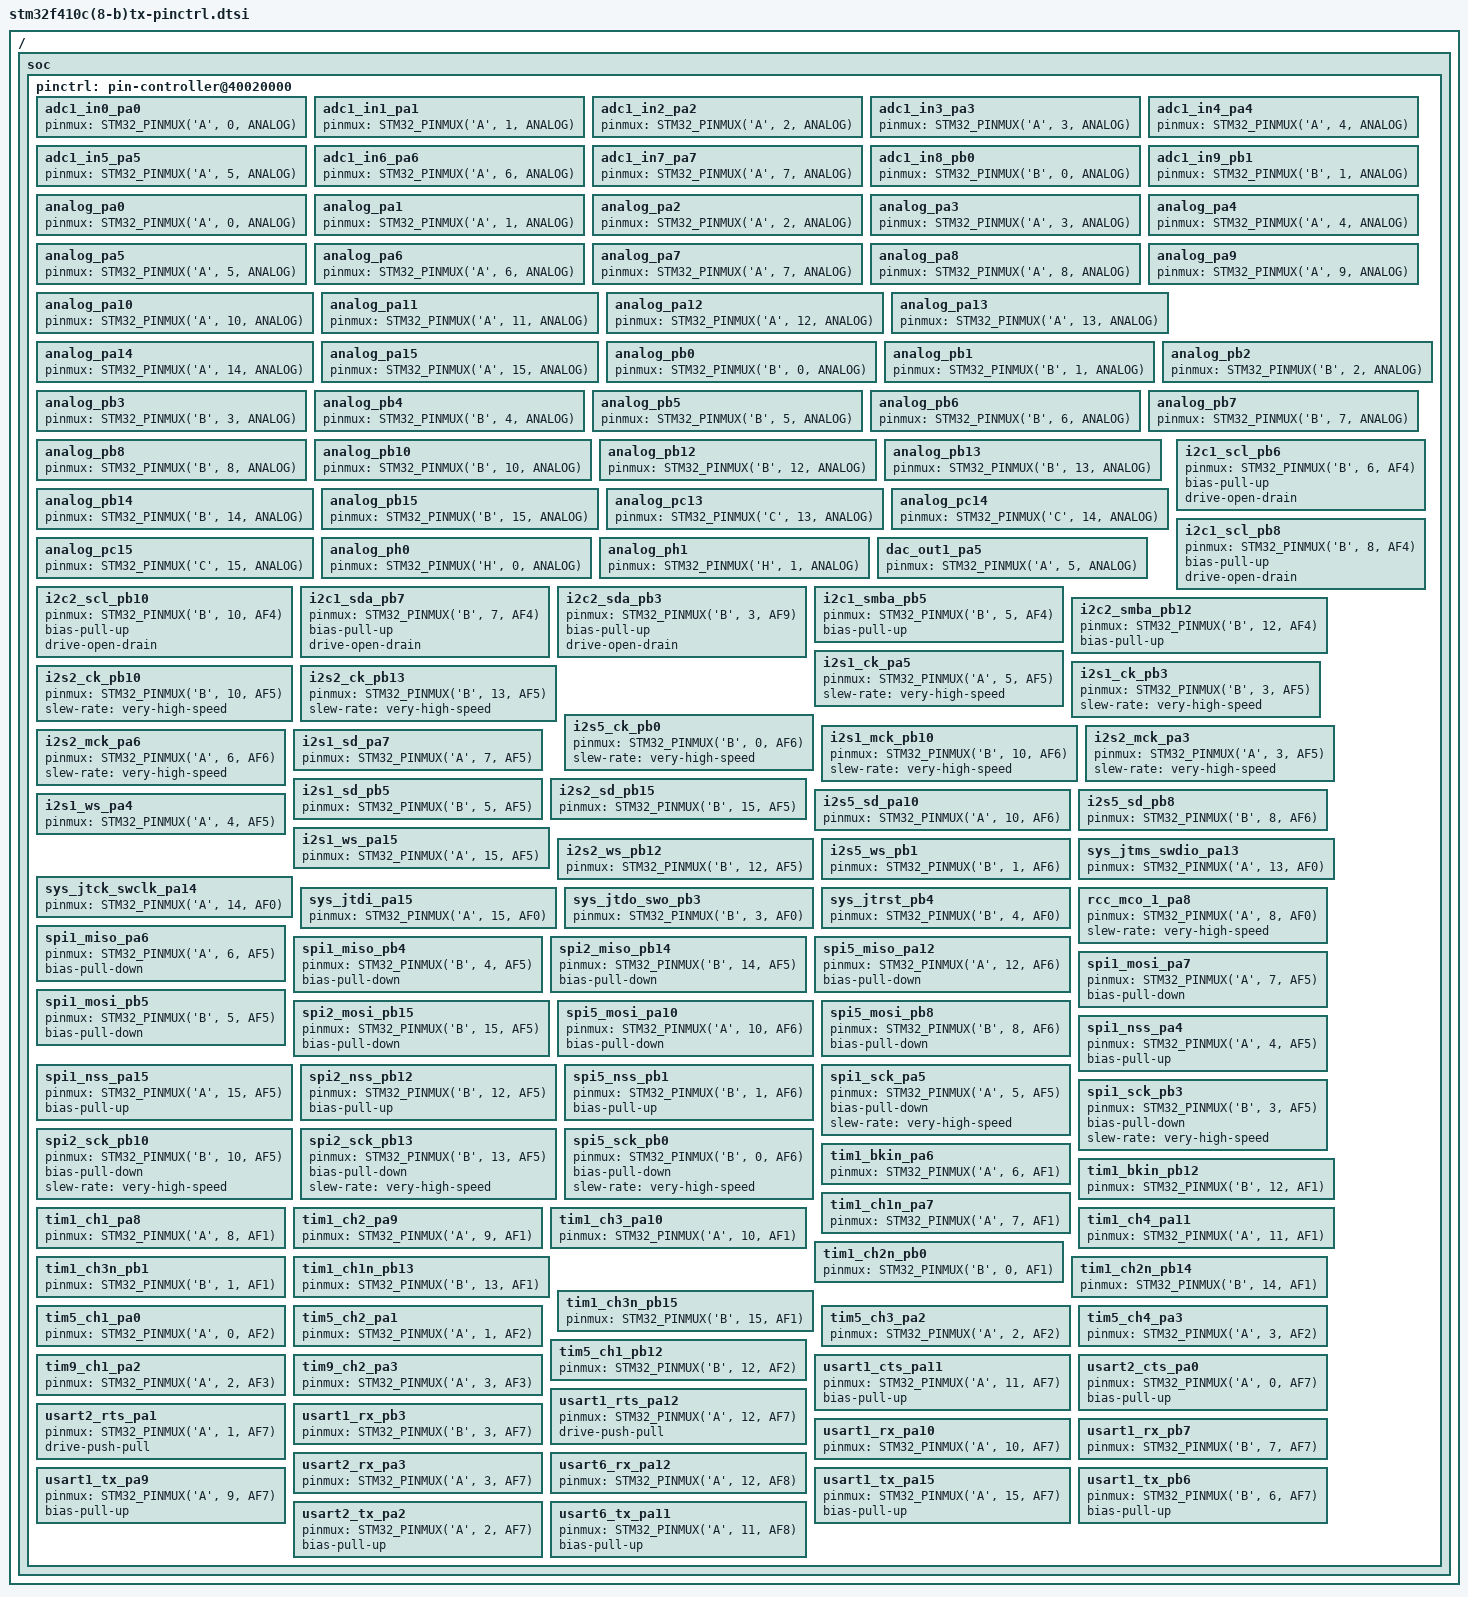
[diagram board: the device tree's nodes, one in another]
/*
 * NOTE: Autogenerated file using genpinctrl.py
 *
 * SPDX-License-Identifier: Apache-2.0
 */

#include <zephyr/dt-bindings/pinctrl/stm32-pinctrl.h>

/ {
	soc {
		pinctrl: pin-controller@40020000 {

			/* ADC_IN / ADC_INN / ADC_INP */

			/omit-if-no-ref/ adc1_in0_pa0: adc1_in0_pa0 {
				pinmux = <STM32_PINMUX('A', 0, ANALOG)>;
			};

			/omit-if-no-ref/ adc1_in1_pa1: adc1_in1_pa1 {
				pinmux = <STM32_PINMUX('A', 1, ANALOG)>;
			};

			/omit-if-no-ref/ adc1_in2_pa2: adc1_in2_pa2 {
				pinmux = <STM32_PINMUX('A', 2, ANALOG)>;
			};

			/omit-if-no-ref/ adc1_in3_pa3: adc1_in3_pa3 {
				pinmux = <STM32_PINMUX('A', 3, ANALOG)>;
			};

			/omit-if-no-ref/ adc1_in4_pa4: adc1_in4_pa4 {
				pinmux = <STM32_PINMUX('A', 4, ANALOG)>;
			};

			/omit-if-no-ref/ adc1_in5_pa5: adc1_in5_pa5 {
				pinmux = <STM32_PINMUX('A', 5, ANALOG)>;
			};

			/omit-if-no-ref/ adc1_in6_pa6: adc1_in6_pa6 {
				pinmux = <STM32_PINMUX('A', 6, ANALOG)>;
			};

			/omit-if-no-ref/ adc1_in7_pa7: adc1_in7_pa7 {
				pinmux = <STM32_PINMUX('A', 7, ANALOG)>;
			};

			/omit-if-no-ref/ adc1_in8_pb0: adc1_in8_pb0 {
				pinmux = <STM32_PINMUX('B', 0, ANALOG)>;
			};

			/omit-if-no-ref/ adc1_in9_pb1: adc1_in9_pb1 {
				pinmux = <STM32_PINMUX('B', 1, ANALOG)>;
			};

			/* Analog */

			/omit-if-no-ref/ analog_pa0: analog_pa0 {
				pinmux = <STM32_PINMUX('A', 0, ANALOG)>;
			};

			/omit-if-no-ref/ analog_pa1: analog_pa1 {
				pinmux = <STM32_PINMUX('A', 1, ANALOG)>;
			};

			/omit-if-no-ref/ analog_pa2: analog_pa2 {
				pinmux = <STM32_PINMUX('A', 2, ANALOG)>;
			};

			/omit-if-no-ref/ analog_pa3: analog_pa3 {
				pinmux = <STM32_PINMUX('A', 3, ANALOG)>;
			};

			/omit-if-no-ref/ analog_pa4: analog_pa4 {
				pinmux = <STM32_PINMUX('A', 4, ANALOG)>;
			};

			/omit-if-no-ref/ analog_pa5: analog_pa5 {
				pinmux = <STM32_PINMUX('A', 5, ANALOG)>;
			};

			/omit-if-no-ref/ analog_pa6: analog_pa6 {
				pinmux = <STM32_PINMUX('A', 6, ANALOG)>;
			};

			/omit-if-no-ref/ analog_pa7: analog_pa7 {
				pinmux = <STM32_PINMUX('A', 7, ANALOG)>;
			};

			/omit-if-no-ref/ analog_pa8: analog_pa8 {
				pinmux = <STM32_PINMUX('A', 8, ANALOG)>;
			};

			/omit-if-no-ref/ analog_pa9: analog_pa9 {
				pinmux = <STM32_PINMUX('A', 9, ANALOG)>;
			};

			/omit-if-no-ref/ analog_pa10: analog_pa10 {
				pinmux = <STM32_PINMUX('A', 10, ANALOG)>;
			};

			/omit-if-no-ref/ analog_pa11: analog_pa11 {
				pinmux = <STM32_PINMUX('A', 11, ANALOG)>;
			};

			/omit-if-no-ref/ analog_pa12: analog_pa12 {
				pinmux = <STM32_PINMUX('A', 12, ANALOG)>;
			};

			/omit-if-no-ref/ analog_pa13: analog_pa13 {
				pinmux = <STM32_PINMUX('A', 13, ANALOG)>;
			};

			/omit-if-no-ref/ analog_pa14: analog_pa14 {
				pinmux = <STM32_PINMUX('A', 14, ANALOG)>;
			};

			/omit-if-no-ref/ analog_pa15: analog_pa15 {
				pinmux = <STM32_PINMUX('A', 15, ANALOG)>;
			};

			/omit-if-no-ref/ analog_pb0: analog_pb0 {
				pinmux = <STM32_PINMUX('B', 0, ANALOG)>;
			};

			/omit-if-no-ref/ analog_pb1: analog_pb1 {
				pinmux = <STM32_PINMUX('B', 1, ANALOG)>;
			};

			/omit-if-no-ref/ analog_pb2: analog_pb2 {
				pinmux = <STM32_PINMUX('B', 2, ANALOG)>;
			};

			/omit-if-no-ref/ analog_pb3: analog_pb3 {
				pinmux = <STM32_PINMUX('B', 3, ANALOG)>;
			};

			/omit-if-no-ref/ analog_pb4: analog_pb4 {
				pinmux = <STM32_PINMUX('B', 4, ANALOG)>;
			};

			/omit-if-no-ref/ analog_pb5: analog_pb5 {
				pinmux = <STM32_PINMUX('B', 5, ANALOG)>;
			};

			/omit-if-no-ref/ analog_pb6: analog_pb6 {
				pinmux = <STM32_PINMUX('B', 6, ANALOG)>;
			};

			/omit-if-no-ref/ analog_pb7: analog_pb7 {
				pinmux = <STM32_PINMUX('B', 7, ANALOG)>;
			};

			/omit-if-no-ref/ analog_pb8: analog_pb8 {
				pinmux = <STM32_PINMUX('B', 8, ANALOG)>;
			};

			/omit-if-no-ref/ analog_pb10: analog_pb10 {
				pinmux = <STM32_PINMUX('B', 10, ANALOG)>;
			};

			/omit-if-no-ref/ analog_pb12: analog_pb12 {
				pinmux = <STM32_PINMUX('B', 12, ANALOG)>;
			};

			/omit-if-no-ref/ analog_pb13: analog_pb13 {
				pinmux = <STM32_PINMUX('B', 13, ANALOG)>;
			};

			/omit-if-no-ref/ analog_pb14: analog_pb14 {
				pinmux = <STM32_PINMUX('B', 14, ANALOG)>;
			};

			/omit-if-no-ref/ analog_pb15: analog_pb15 {
				pinmux = <STM32_PINMUX('B', 15, ANALOG)>;
			};

			/omit-if-no-ref/ analog_pc13: analog_pc13 {
				pinmux = <STM32_PINMUX('C', 13, ANALOG)>;
			};

			/omit-if-no-ref/ analog_pc14: analog_pc14 {
				pinmux = <STM32_PINMUX('C', 14, ANALOG)>;
			};

			/omit-if-no-ref/ analog_pc15: analog_pc15 {
				pinmux = <STM32_PINMUX('C', 15, ANALOG)>;
			};

			/omit-if-no-ref/ analog_ph0: analog_ph0 {
				pinmux = <STM32_PINMUX('H', 0, ANALOG)>;
			};

			/omit-if-no-ref/ analog_ph1: analog_ph1 {
				pinmux = <STM32_PINMUX('H', 1, ANALOG)>;
			};

			/* DAC_OUT */

			/omit-if-no-ref/ dac_out1_pa5: dac_out1_pa5 {
				pinmux = <STM32_PINMUX('A', 5, ANALOG)>;
			};

			/* I2C_SCL */

			/omit-if-no-ref/ i2c1_scl_pb6: i2c1_scl_pb6 {
				pinmux = <STM32_PINMUX('B', 6, AF4)>;
				bias-pull-up;
				drive-open-drain;
			};

			/omit-if-no-ref/ i2c1_scl_pb8: i2c1_scl_pb8 {
				pinmux = <STM32_PINMUX('B', 8, AF4)>;
				bias-pull-up;
				drive-open-drain;
			};

			/omit-if-no-ref/ i2c2_scl_pb10: i2c2_scl_pb10 {
				pinmux = <STM32_PINMUX('B', 10, AF4)>;
				bias-pull-up;
				drive-open-drain;
			};

			/* I2C_SDA */

			/omit-if-no-ref/ i2c1_sda_pb7: i2c1_sda_pb7 {
				pinmux = <STM32_PINMUX('B', 7, AF4)>;
				bias-pull-up;
				drive-open-drain;
			};

			/omit-if-no-ref/ i2c2_sda_pb3: i2c2_sda_pb3 {
				pinmux = <STM32_PINMUX('B', 3, AF9)>;
				bias-pull-up;
				drive-open-drain;
			};

			/* I2C_SMBA */

			/omit-if-no-ref/ i2c1_smba_pb5: i2c1_smba_pb5 {
				pinmux = <STM32_PINMUX('B', 5, AF4)>;
				bias-pull-up;
			};

			/omit-if-no-ref/ i2c2_smba_pb12: i2c2_smba_pb12 {
				pinmux = <STM32_PINMUX('B', 12, AF4)>;
				bias-pull-up;
			};

			/* I2S_CK */

			/omit-if-no-ref/ i2s1_ck_pa5: i2s1_ck_pa5 {
				pinmux = <STM32_PINMUX('A', 5, AF5)>;
				slew-rate = "very-high-speed";
			};

			/omit-if-no-ref/ i2s1_ck_pb3: i2s1_ck_pb3 {
				pinmux = <STM32_PINMUX('B', 3, AF5)>;
				slew-rate = "very-high-speed";
			};

			/omit-if-no-ref/ i2s2_ck_pb10: i2s2_ck_pb10 {
				pinmux = <STM32_PINMUX('B', 10, AF5)>;
				slew-rate = "very-high-speed";
			};

			/omit-if-no-ref/ i2s2_ck_pb13: i2s2_ck_pb13 {
				pinmux = <STM32_PINMUX('B', 13, AF5)>;
				slew-rate = "very-high-speed";
			};

			/omit-if-no-ref/ i2s5_ck_pb0: i2s5_ck_pb0 {
				pinmux = <STM32_PINMUX('B', 0, AF6)>;
				slew-rate = "very-high-speed";
			};

			/* I2S_MCK */

			/omit-if-no-ref/ i2s1_mck_pb10: i2s1_mck_pb10 {
				pinmux = <STM32_PINMUX('B', 10, AF6)>;
				slew-rate = "very-high-speed";
			};

			/omit-if-no-ref/ i2s2_mck_pa3: i2s2_mck_pa3 {
				pinmux = <STM32_PINMUX('A', 3, AF5)>;
				slew-rate = "very-high-speed";
			};

			/omit-if-no-ref/ i2s2_mck_pa6: i2s2_mck_pa6 {
				pinmux = <STM32_PINMUX('A', 6, AF6)>;
				slew-rate = "very-high-speed";
			};

			/* I2S_SD */

			/omit-if-no-ref/ i2s1_sd_pa7: i2s1_sd_pa7 {
				pinmux = <STM32_PINMUX('A', 7, AF5)>;
			};

			/omit-if-no-ref/ i2s1_sd_pb5: i2s1_sd_pb5 {
				pinmux = <STM32_PINMUX('B', 5, AF5)>;
			};

			/omit-if-no-ref/ i2s2_sd_pb15: i2s2_sd_pb15 {
				pinmux = <STM32_PINMUX('B', 15, AF5)>;
			};

			/omit-if-no-ref/ i2s5_sd_pa10: i2s5_sd_pa10 {
				pinmux = <STM32_PINMUX('A', 10, AF6)>;
			};

			/omit-if-no-ref/ i2s5_sd_pb8: i2s5_sd_pb8 {
				pinmux = <STM32_PINMUX('B', 8, AF6)>;
			};

			/* I2S_WS */

			/omit-if-no-ref/ i2s1_ws_pa4: i2s1_ws_pa4 {
				pinmux = <STM32_PINMUX('A', 4, AF5)>;
			};

			/omit-if-no-ref/ i2s1_ws_pa15: i2s1_ws_pa15 {
				pinmux = <STM32_PINMUX('A', 15, AF5)>;
			};

			/omit-if-no-ref/ i2s2_ws_pb12: i2s2_ws_pb12 {
				pinmux = <STM32_PINMUX('B', 12, AF5)>;
			};

			/omit-if-no-ref/ i2s5_ws_pb1: i2s5_ws_pb1 {
				pinmux = <STM32_PINMUX('B', 1, AF6)>;
			};

			/* JTAG PORT */

			/omit-if-no-ref/ sys_jtms_swdio_pa13: sys_jtms_swdio_pa13 {
				pinmux = <STM32_PINMUX('A', 13, AF0)>;
			};

			/omit-if-no-ref/ sys_jtck_swclk_pa14: sys_jtck_swclk_pa14 {
				pinmux = <STM32_PINMUX('A', 14, AF0)>;
			};

			/omit-if-no-ref/ sys_jtdi_pa15: sys_jtdi_pa15 {
				pinmux = <STM32_PINMUX('A', 15, AF0)>;
			};

			/omit-if-no-ref/ sys_jtdo_swo_pb3: sys_jtdo_swo_pb3 {
				pinmux = <STM32_PINMUX('B', 3, AF0)>;
			};

			/omit-if-no-ref/ sys_jtrst_pb4: sys_jtrst_pb4 {
				pinmux = <STM32_PINMUX('B', 4, AF0)>;
			};

			/* RCC_MCO */

			/omit-if-no-ref/ rcc_mco_1_pa8: rcc_mco_1_pa8 {
				pinmux = <STM32_PINMUX('A', 8, AF0)>;
				slew-rate = "very-high-speed";
			};

			/* SPI_MISO */

			/omit-if-no-ref/ spi1_miso_pa6: spi1_miso_pa6 {
				pinmux = <STM32_PINMUX('A', 6, AF5)>;
				bias-pull-down;
			};

			/omit-if-no-ref/ spi1_miso_pb4: spi1_miso_pb4 {
				pinmux = <STM32_PINMUX('B', 4, AF5)>;
				bias-pull-down;
			};

			/omit-if-no-ref/ spi2_miso_pb14: spi2_miso_pb14 {
				pinmux = <STM32_PINMUX('B', 14, AF5)>;
				bias-pull-down;
			};

			/omit-if-no-ref/ spi5_miso_pa12: spi5_miso_pa12 {
				pinmux = <STM32_PINMUX('A', 12, AF6)>;
				bias-pull-down;
			};

			/* SPI_MOSI */

			/omit-if-no-ref/ spi1_mosi_pa7: spi1_mosi_pa7 {
				pinmux = <STM32_PINMUX('A', 7, AF5)>;
				bias-pull-down;
			};

			/omit-if-no-ref/ spi1_mosi_pb5: spi1_mosi_pb5 {
				pinmux = <STM32_PINMUX('B', 5, AF5)>;
				bias-pull-down;
			};

			/omit-if-no-ref/ spi2_mosi_pb15: spi2_mosi_pb15 {
				pinmux = <STM32_PINMUX('B', 15, AF5)>;
				bias-pull-down;
			};

			/omit-if-no-ref/ spi5_mosi_pa10: spi5_mosi_pa10 {
				pinmux = <STM32_PINMUX('A', 10, AF6)>;
				bias-pull-down;
			};

			/omit-if-no-ref/ spi5_mosi_pb8: spi5_mosi_pb8 {
				pinmux = <STM32_PINMUX('B', 8, AF6)>;
				bias-pull-down;
			};

			/* SPI_NSS */

			/omit-if-no-ref/ spi1_nss_pa4: spi1_nss_pa4 {
				pinmux = <STM32_PINMUX('A', 4, AF5)>;
				bias-pull-up;
			};

			/omit-if-no-ref/ spi1_nss_pa15: spi1_nss_pa15 {
				pinmux = <STM32_PINMUX('A', 15, AF5)>;
				bias-pull-up;
			};

			/omit-if-no-ref/ spi2_nss_pb12: spi2_nss_pb12 {
				pinmux = <STM32_PINMUX('B', 12, AF5)>;
				bias-pull-up;
			};

			/omit-if-no-ref/ spi5_nss_pb1: spi5_nss_pb1 {
				pinmux = <STM32_PINMUX('B', 1, AF6)>;
				bias-pull-up;
			};

			/* SPI_SCK */

			/omit-if-no-ref/ spi1_sck_pa5: spi1_sck_pa5 {
				pinmux = <STM32_PINMUX('A', 5, AF5)>;
				bias-pull-down;
				slew-rate = "very-high-speed";
			};

			/omit-if-no-ref/ spi1_sck_pb3: spi1_sck_pb3 {
				pinmux = <STM32_PINMUX('B', 3, AF5)>;
				bias-pull-down;
				slew-rate = "very-high-speed";
			};

			/omit-if-no-ref/ spi2_sck_pb10: spi2_sck_pb10 {
				pinmux = <STM32_PINMUX('B', 10, AF5)>;
				bias-pull-down;
				slew-rate = "very-high-speed";
			};

			/omit-if-no-ref/ spi2_sck_pb13: spi2_sck_pb13 {
				pinmux = <STM32_PINMUX('B', 13, AF5)>;
				bias-pull-down;
				slew-rate = "very-high-speed";
			};

			/omit-if-no-ref/ spi5_sck_pb0: spi5_sck_pb0 {
				pinmux = <STM32_PINMUX('B', 0, AF6)>;
				bias-pull-down;
				slew-rate = "very-high-speed";
			};

			/* TIM_BKIN */

			/omit-if-no-ref/ tim1_bkin_pa6: tim1_bkin_pa6 {
				pinmux = <STM32_PINMUX('A', 6, AF1)>;
			};

			/omit-if-no-ref/ tim1_bkin_pb12: tim1_bkin_pb12 {
				pinmux = <STM32_PINMUX('B', 12, AF1)>;
			};

			/* TIM_CH / TIM_CHN */

			/omit-if-no-ref/ tim1_ch1n_pa7: tim1_ch1n_pa7 {
				pinmux = <STM32_PINMUX('A', 7, AF1)>;
			};

			/omit-if-no-ref/ tim1_ch1_pa8: tim1_ch1_pa8 {
				pinmux = <STM32_PINMUX('A', 8, AF1)>;
			};

			/omit-if-no-ref/ tim1_ch2_pa9: tim1_ch2_pa9 {
				pinmux = <STM32_PINMUX('A', 9, AF1)>;
			};

			/omit-if-no-ref/ tim1_ch3_pa10: tim1_ch3_pa10 {
				pinmux = <STM32_PINMUX('A', 10, AF1)>;
			};

			/omit-if-no-ref/ tim1_ch4_pa11: tim1_ch4_pa11 {
				pinmux = <STM32_PINMUX('A', 11, AF1)>;
			};

			/omit-if-no-ref/ tim1_ch2n_pb0: tim1_ch2n_pb0 {
				pinmux = <STM32_PINMUX('B', 0, AF1)>;
			};

			/omit-if-no-ref/ tim1_ch3n_pb1: tim1_ch3n_pb1 {
				pinmux = <STM32_PINMUX('B', 1, AF1)>;
			};

			/omit-if-no-ref/ tim1_ch1n_pb13: tim1_ch1n_pb13 {
				pinmux = <STM32_PINMUX('B', 13, AF1)>;
			};

			/omit-if-no-ref/ tim1_ch2n_pb14: tim1_ch2n_pb14 {
				pinmux = <STM32_PINMUX('B', 14, AF1)>;
			};

			/omit-if-no-ref/ tim1_ch3n_pb15: tim1_ch3n_pb15 {
				pinmux = <STM32_PINMUX('B', 15, AF1)>;
			};

			/omit-if-no-ref/ tim5_ch1_pa0: tim5_ch1_pa0 {
				pinmux = <STM32_PINMUX('A', 0, AF2)>;
			};

			/omit-if-no-ref/ tim5_ch2_pa1: tim5_ch2_pa1 {
				pinmux = <STM32_PINMUX('A', 1, AF2)>;
			};

			/omit-if-no-ref/ tim5_ch3_pa2: tim5_ch3_pa2 {
				pinmux = <STM32_PINMUX('A', 2, AF2)>;
			};

			/omit-if-no-ref/ tim5_ch4_pa3: tim5_ch4_pa3 {
				pinmux = <STM32_PINMUX('A', 3, AF2)>;
			};

			/omit-if-no-ref/ tim5_ch1_pb12: tim5_ch1_pb12 {
				pinmux = <STM32_PINMUX('B', 12, AF2)>;
			};

			/omit-if-no-ref/ tim9_ch1_pa2: tim9_ch1_pa2 {
				pinmux = <STM32_PINMUX('A', 2, AF3)>;
			};

			/omit-if-no-ref/ tim9_ch2_pa3: tim9_ch2_pa3 {
				pinmux = <STM32_PINMUX('A', 3, AF3)>;
			};

			/* UART_CTS / USART_CTS / LPUART_CTS */

			/omit-if-no-ref/ usart1_cts_pa11: usart1_cts_pa11 {
				pinmux = <STM32_PINMUX('A', 11, AF7)>;
				bias-pull-up;
			};

			/omit-if-no-ref/ usart2_cts_pa0: usart2_cts_pa0 {
				pinmux = <STM32_PINMUX('A', 0, AF7)>;
				bias-pull-up;
			};

			/* UART_RTS / USART_RTS / LPUART_RTS */

			/omit-if-no-ref/ usart1_rts_pa12: usart1_rts_pa12 {
				pinmux = <STM32_PINMUX('A', 12, AF7)>;
				drive-push-pull;
			};

			/omit-if-no-ref/ usart2_rts_pa1: usart2_rts_pa1 {
				pinmux = <STM32_PINMUX('A', 1, AF7)>;
				drive-push-pull;
			};

			/* UART_RX / USART_RX / LPUART_RX */

			/omit-if-no-ref/ usart1_rx_pa10: usart1_rx_pa10 {
				pinmux = <STM32_PINMUX('A', 10, AF7)>;
			};

			/omit-if-no-ref/ usart1_rx_pb3: usart1_rx_pb3 {
				pinmux = <STM32_PINMUX('B', 3, AF7)>;
			};

			/omit-if-no-ref/ usart1_rx_pb7: usart1_rx_pb7 {
				pinmux = <STM32_PINMUX('B', 7, AF7)>;
			};

			/omit-if-no-ref/ usart2_rx_pa3: usart2_rx_pa3 {
				pinmux = <STM32_PINMUX('A', 3, AF7)>;
			};

			/omit-if-no-ref/ usart6_rx_pa12: usart6_rx_pa12 {
				pinmux = <STM32_PINMUX('A', 12, AF8)>;
			};

			/* UART_TX / USART_TX / LPUART_TX */

			/omit-if-no-ref/ usart1_tx_pa9: usart1_tx_pa9 {
				pinmux = <STM32_PINMUX('A', 9, AF7)>;
				bias-pull-up;
			};

			/omit-if-no-ref/ usart1_tx_pa15: usart1_tx_pa15 {
				pinmux = <STM32_PINMUX('A', 15, AF7)>;
				bias-pull-up;
			};

			/omit-if-no-ref/ usart1_tx_pb6: usart1_tx_pb6 {
				pinmux = <STM32_PINMUX('B', 6, AF7)>;
				bias-pull-up;
			};

			/omit-if-no-ref/ usart2_tx_pa2: usart2_tx_pa2 {
				pinmux = <STM32_PINMUX('A', 2, AF7)>;
				bias-pull-up;
			};

			/omit-if-no-ref/ usart6_tx_pa11: usart6_tx_pa11 {
				pinmux = <STM32_PINMUX('A', 11, AF8)>;
				bias-pull-up;
			};

		};
	};
};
